# TM4C129ENCPDT register map
File version: 1.0
CPU: CORTEX_M4 1.0, other endian, MPU, FPU, 3 interrupt priority bits
Registers are 32-bit, read-write, reset 0x0 unless marked. A register's access mark holds for its fields unless they carry their own. Offsets are from the block's base; [hi:lo] are bit positions.

## I2C0 — I2C register offsets
Base 0x40020000
Same registers: I2C1 0x40021000, I2C2 0x40022000, I2C3 0x40023000, I2C8 0x400B8000, I2C9 0x400B9000, I2C4 0x400C0000, I2C5 0x400C1000, I2C6 0x400C2000, I2C7 0x400C3000
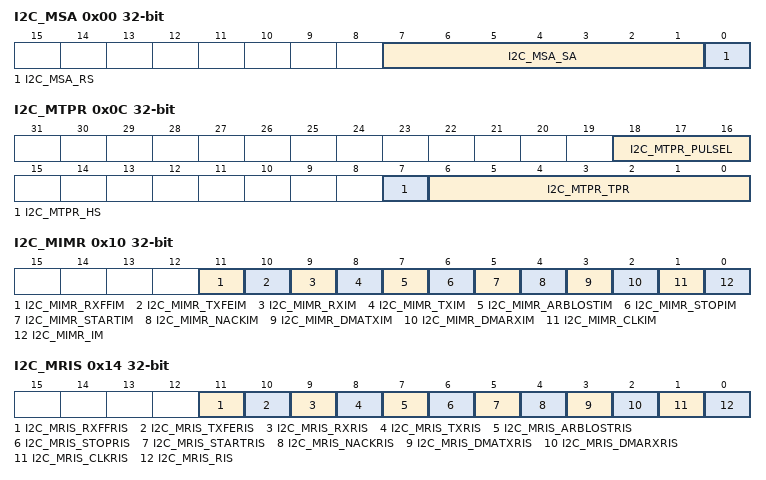
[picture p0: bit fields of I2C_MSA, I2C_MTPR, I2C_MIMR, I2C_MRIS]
0x00 I2C_MSA — I2C Master Slave Address
  [7:1] I2C_MSA_SA — [7:1] I2C Slave Address
  [0] I2C_MSA_RS — [0:0] Receive not send
0x04 I2C_MCS — I2C Master Control/Status
  [31] I2C_MCS_ACTDMARX — [31:31] DMA RX Active Status
  [30] I2C_MCS_ACTDMATX — [30:30] DMA TX Active Status
  [7] I2C_MCS_CLKTO — [7:7] Clock Timeout Error
  [6] I2C_MCS_BURST — [6:6] Burst Enable
  [6] I2C_MCS_BUSBSY — [6:6] Bus Busy
  [5] I2C_MCS_IDLE — [5:5] I2C Idle
  [5] I2C_MCS_QCMD — [5:5] Quick Command
  [4] I2C_MCS_ARBLST — [4:4] Arbitration Lost
  [4] I2C_MCS_HS — [4:4] High-Speed Enable
  [3] I2C_MCS_ACK — [3:3] Data Acknowledge Enable
  [3] I2C_MCS_DATACK — [3:3] Acknowledge Data
  [2] I2C_MCS_ADRACK — [2:2] Acknowledge Address
  [2] I2C_MCS_STOP — [2:2] Generate STOP
  [1] I2C_MCS_ERROR — [1:1] Error
  [1] I2C_MCS_START — [1:1] Generate START
  [0] I2C_MCS_RUN — [0:0] I2C Master Enable
  [0] I2C_MCS_BUSY — [0:0] I2C Busy
0x08 I2C_MDR — I2C Master Data
  [7:0] I2C_MDR_DATA — [7:0] This byte contains the data transferred during a transaction
0x0C I2C_MTPR — I2C Master Timer Period
  [18:16] I2C_MTPR_PULSEL — [18:16] Glitch Suppression Pulse Width
    0=I2C_MTPR_PULSEL_BYPASS (Bypass); 0x10000=1 clock; 0x20000=2 clocks; 0x30000=3 clocks; 0x40000=4 clocks; 0x50000=8 clocks; 0x60000=16 clocks; 0x70000=31 clocks
  [7] I2C_MTPR_HS — [7:7] High-Speed Enable
  [6:0] I2C_MTPR_TPR — [6:0] Timer Period
0x10 I2C_MIMR — I2C Master Interrupt Mask
  [11] I2C_MIMR_RXFFIM — [11:11] Receive FIFO Full Interrupt Mask
  [10] I2C_MIMR_TXFEIM — [10:10] Transmit FIFO Empty Interrupt Mask
  [9] I2C_MIMR_RXIM — [9:9] Receive FIFO Request Interrupt Mask
  [8] I2C_MIMR_TXIM — [8:8] Transmit FIFO Request Interrupt Mask
  [7] I2C_MIMR_ARBLOSTIM — [7:7] Arbitration Lost Interrupt Mask
  [6] I2C_MIMR_STOPIM — [6:6] STOP Detection Interrupt Mask
  [5] I2C_MIMR_STARTIM — [5:5] START Detection Interrupt Mask
  [4] I2C_MIMR_NACKIM — [4:4] Address/Data NACK Interrupt Mask
  [3] I2C_MIMR_DMATXIM — [3:3] Transmit DMA Interrupt Mask
  [2] I2C_MIMR_DMARXIM — [2:2] Receive DMA Interrupt Mask
  [1] I2C_MIMR_CLKIM — [1:1] Clock Timeout Interrupt Mask
  [0] I2C_MIMR_IM — [0:0] Master Interrupt Mask
0x14 I2C_MRIS — I2C Master Raw Interrupt Status
  [11] I2C_MRIS_RXFFRIS — [11:11] Receive FIFO Full Raw Interrupt Status
  [10] I2C_MRIS_TXFERIS — [10:10] Transmit FIFO Empty Raw Interrupt Status
  [9] I2C_MRIS_RXRIS — [9:9] Receive FIFO Request Raw Interrupt Status
  [8] I2C_MRIS_TXRIS — [8:8] Transmit Request Raw Interrupt Status
  [7] I2C_MRIS_ARBLOSTRIS — [7:7] Arbitration Lost Raw Interrupt Status
  [6] I2C_MRIS_STOPRIS — [6:6] STOP Detection Raw Interrupt Status
  [5] I2C_MRIS_STARTRIS — [5:5] START Detection Raw Interrupt Status
  [4] I2C_MRIS_NACKRIS — [4:4] Address/Data NACK Raw Interrupt Status
  [3] I2C_MRIS_DMATXRIS — [3:3] Transmit DMA Raw Interrupt Status
  [2] I2C_MRIS_DMARXRIS — [2:2] Receive DMA Raw Interrupt Status
  [1] I2C_MRIS_CLKRIS — [1:1] Clock Timeout Raw Interrupt Status
  [0] I2C_MRIS_RIS — [0:0] Master Raw Interrupt Status
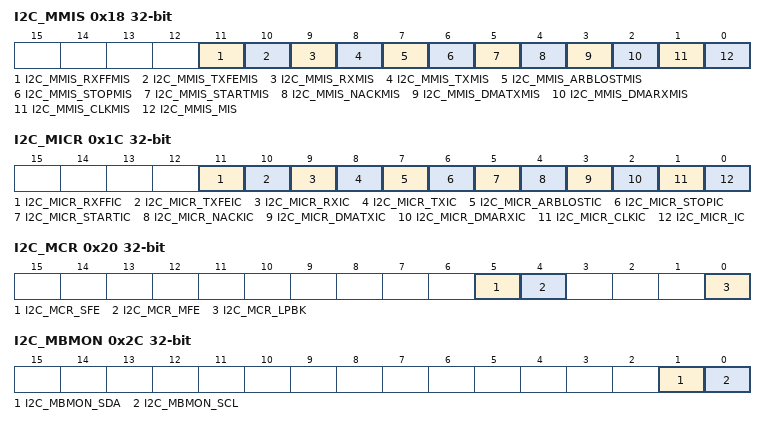
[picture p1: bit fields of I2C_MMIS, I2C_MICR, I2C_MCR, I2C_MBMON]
0x18 I2C_MMIS — I2C Master Masked Interrupt Status
  [11] I2C_MMIS_RXFFMIS — [11:11] Receive FIFO Full Interrupt Mask
  [10] I2C_MMIS_TXFEMIS — [10:10] Transmit FIFO Empty Interrupt Mask
  [9] I2C_MMIS_RXMIS — [9:9] Receive FIFO Request Interrupt Mask
  [8] I2C_MMIS_TXMIS — [8:8] Transmit Request Interrupt Mask
  [7] I2C_MMIS_ARBLOSTMIS — [7:7] Arbitration Lost Interrupt Mask
  [6] I2C_MMIS_STOPMIS — [6:6] STOP Detection Interrupt Mask
  [5] I2C_MMIS_STARTMIS — [5:5] START Detection Interrupt Mask
  [4] I2C_MMIS_NACKMIS — [4:4] Address/Data NACK Interrupt Mask
  [3] I2C_MMIS_DMATXMIS — [3:3] Transmit DMA Interrupt Status
  [2] I2C_MMIS_DMARXMIS — [2:2] Receive DMA Interrupt Status
  [1] I2C_MMIS_CLKMIS — [1:1] Clock Timeout Masked Interrupt Status
  [0] I2C_MMIS_MIS — [0:0] Masked Interrupt Status
0x1C I2C_MICR — I2C Master Interrupt Clear
  [11] I2C_MICR_RXFFIC — [11:11] Receive FIFO Full Interrupt Clear
  [10] I2C_MICR_TXFEIC — [10:10] Transmit FIFO Empty Interrupt Clear
  [9] I2C_MICR_RXIC — [9:9] Receive FIFO Request Interrupt Clear
  [8] I2C_MICR_TXIC — [8:8] Transmit FIFO Request Interrupt Clear
  [7] I2C_MICR_ARBLOSTIC — [7:7] Arbitration Lost Interrupt Clear
  [6] I2C_MICR_STOPIC — [6:6] STOP Detection Interrupt Clear
  [5] I2C_MICR_STARTIC — [5:5] START Detection Interrupt Clear
  [4] I2C_MICR_NACKIC — [4:4] Address/Data NACK Interrupt Clear
  [3] I2C_MICR_DMATXIC — [3:3] Transmit DMA Interrupt Clear
  [2] I2C_MICR_DMARXIC — [2:2] Receive DMA Interrupt Clear
  [1] I2C_MICR_CLKIC — [1:1] Clock Timeout Interrupt Clear
  [0] I2C_MICR_IC — [0:0] Master Interrupt Clear
0x20 I2C_MCR — I2C Master Configuration
  [5] I2C_MCR_SFE — [5:5] I2C Slave Function Enable
  [4] I2C_MCR_MFE — [4:4] I2C Master Function Enable
  [0] I2C_MCR_LPBK — [0:0] I2C Loopback
0x24 I2C_MCLKOCNT — I2C Master Clock Low Timeout Count
  [7:0] I2C_MCLKOCNT_CNTL — [7:0] I2C Master Count
0x2C I2C_MBMON — I2C Master Bus Monitor
  [1] I2C_MBMON_SDA — [1:1] I2C SDA Status
  [0] I2C_MBMON_SCL — [0:0] I2C SCL Status
0x30 I2C_MBLEN — I2C Master Burst Length
  [7:0] I2C_MBLEN_CNTL — [7:0] I2C Burst Length
0x34 I2C_MBCNT — I2C Master Burst Count
  [7:0] I2C_MBCNT_CNTL — [7:0] I2C Master Burst Count
0x800 I2C_SOAR — I2C Slave Own Address
  [6:0] I2C_SOAR_OAR — [6:0] I2C Slave Own Address
0x804 I2C_SCSR — I2C Slave Control/Status
  [31] I2C_SCSR_ACTDMARX — [31:31] DMA RX Active Status
  [30] I2C_SCSR_ACTDMATX — [30:30] DMA TX Active Status
  [5] I2C_SCSR_QCMDRW — [5:5] Quick Command Read / Write
  [4] I2C_SCSR_QCMDST — [4:4] Quick Command Status
  [3] I2C_SCSR_OAR2SEL — [3:3] OAR2 Address Matched
  [2] I2C_SCSR_FBR — [2:2] First Byte Received
  [2] I2C_SCSR_RXFIFO — [2:2] RX FIFO Enable
  [1] I2C_SCSR_TXFIFO — [1:1] TX FIFO Enable
  [1] I2C_SCSR_TREQ — [1:1] Transmit Request
  [0] I2C_SCSR_DA — [0:0] Device Active
  [0] I2C_SCSR_RREQ — [0:0] Receive Request
0x808 I2C_SDR — I2C Slave Data
  [7:0] I2C_SDR_DATA — [7:0] Data for Transfer
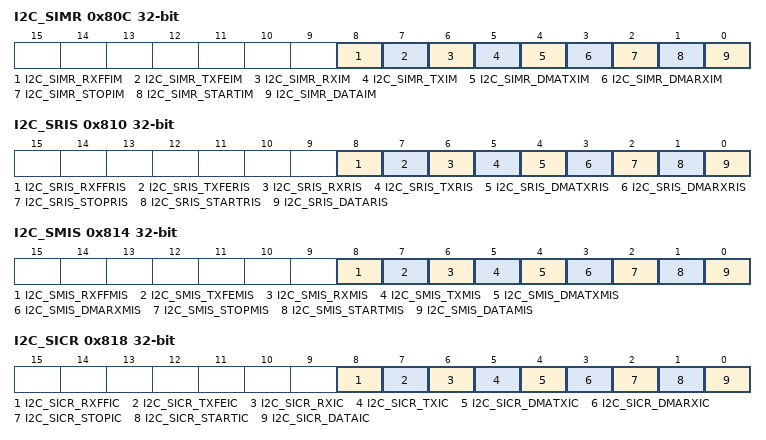
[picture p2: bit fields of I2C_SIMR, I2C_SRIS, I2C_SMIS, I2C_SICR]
0x80C I2C_SIMR — I2C Slave Interrupt Mask
  [8] I2C_SIMR_RXFFIM — [8:8] Receive FIFO Full Interrupt Mask
  [7] I2C_SIMR_TXFEIM — [7:7] Transmit FIFO Empty Interrupt Mask
  [6] I2C_SIMR_RXIM — [6:6] Receive FIFO Request Interrupt Mask
  [5] I2C_SIMR_TXIM — [5:5] Transmit FIFO Request Interrupt Mask
  [4] I2C_SIMR_DMATXIM — [4:4] Transmit DMA Interrupt Mask
  [3] I2C_SIMR_DMARXIM — [3:3] Receive DMA Interrupt Mask
  [2] I2C_SIMR_STOPIM — [2:2] Stop Condition Interrupt Mask
  [1] I2C_SIMR_STARTIM — [1:1] Start Condition Interrupt Mask
  [0] I2C_SIMR_DATAIM — [0:0] Data Interrupt Mask
0x810 I2C_SRIS — I2C Slave Raw Interrupt Status
  [8] I2C_SRIS_RXFFRIS — [8:8] Receive FIFO Full Raw Interrupt Status
  [7] I2C_SRIS_TXFERIS — [7:7] Transmit FIFO Empty Raw Interrupt Status
  [6] I2C_SRIS_RXRIS — [6:6] Receive FIFO Request Raw Interrupt Status
  [5] I2C_SRIS_TXRIS — [5:5] Transmit Request Raw Interrupt Status
  [4] I2C_SRIS_DMATXRIS — [4:4] Transmit DMA Raw Interrupt Status
  [3] I2C_SRIS_DMARXRIS — [3:3] Receive DMA Raw Interrupt Status
  [2] I2C_SRIS_STOPRIS — [2:2] Stop Condition Raw Interrupt Status
  [1] I2C_SRIS_STARTRIS — [1:1] Start Condition Raw Interrupt Status
  [0] I2C_SRIS_DATARIS — [0:0] Data Raw Interrupt Status
0x814 I2C_SMIS — I2C Slave Masked Interrupt Status
  [8] I2C_SMIS_RXFFMIS — [8:8] Receive FIFO Full Interrupt Mask
  [7] I2C_SMIS_TXFEMIS — [7:7] Transmit FIFO Empty Interrupt Mask
  [6] I2C_SMIS_RXMIS — [6:6] Receive FIFO Request Interrupt Mask
  [5] I2C_SMIS_TXMIS — [5:5] Transmit FIFO Request Interrupt Mask
  [4] I2C_SMIS_DMATXMIS — [4:4] Transmit DMA Masked Interrupt Status
  [3] I2C_SMIS_DMARXMIS — [3:3] Receive DMA Masked Interrupt Status
  [2] I2C_SMIS_STOPMIS — [2:2] Stop Condition Masked Interrupt Status
  [1] I2C_SMIS_STARTMIS — [1:1] Start Condition Masked Interrupt Status
  [0] I2C_SMIS_DATAMIS — [0:0] Data Masked Interrupt Status
0x818 I2C_SICR — I2C Slave Interrupt Clear
  [8] I2C_SICR_RXFFIC — [8:8] Receive FIFO Full Interrupt Mask
  [7] I2C_SICR_TXFEIC — [7:7] Transmit FIFO Empty Interrupt Mask
  [6] I2C_SICR_RXIC — [6:6] Receive Request Interrupt Mask
  [5] I2C_SICR_TXIC — [5:5] Transmit Request Interrupt Mask
  [4] I2C_SICR_DMATXIC — [4:4] Transmit DMA Interrupt Clear
  [3] I2C_SICR_DMARXIC — [3:3] Receive DMA Interrupt Clear
  [2] I2C_SICR_STOPIC — [2:2] Stop Condition Interrupt Clear
  [1] I2C_SICR_STARTIC — [1:1] Start Condition Interrupt Clear
  [0] I2C_SICR_DATAIC — [0:0] Data Interrupt Clear
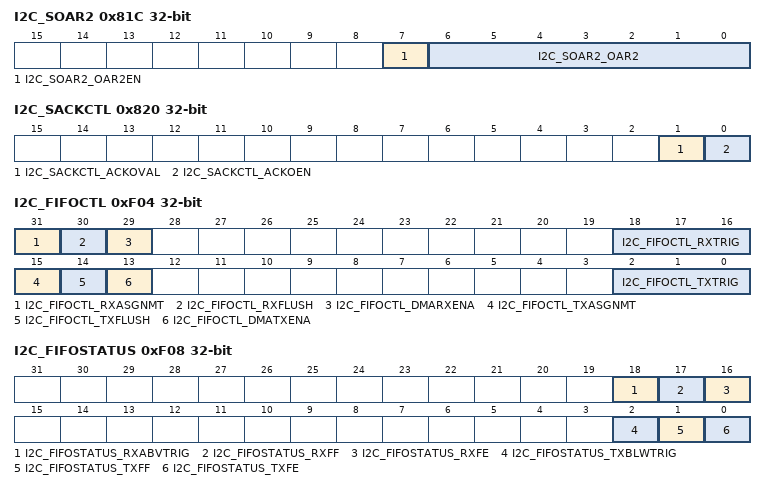
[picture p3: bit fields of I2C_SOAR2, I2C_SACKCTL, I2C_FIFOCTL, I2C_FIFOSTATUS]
0x81C I2C_SOAR2 — I2C Slave Own Address 2
  [7] I2C_SOAR2_OAR2EN — [7:7] I2C Slave Own Address 2 Enable
  [6:0] I2C_SOAR2_OAR2 — [6:0] I2C Slave Own Address 2
0x820 I2C_SACKCTL — I2C Slave ACK Control
  [1] I2C_SACKCTL_ACKOVAL — [1:1] I2C Slave ACK Override Value
  [0] I2C_SACKCTL_ACKOEN — [0:0] I2C Slave ACK Override Enable
0xF00 I2C_FIFODATA
  [7:0] I2C_FIFODATA_DATA — [7:0] I2C TX FIFO Write Data Byte
0xF04 I2C_FIFOCTL — I2C FIFO Control
  [31] I2C_FIFOCTL_RXASGNMT — [31:31] RX Control Assignment
  [30] I2C_FIFOCTL_RXFLUSH — [30:30] RX FIFO Flush
  [29] I2C_FIFOCTL_DMARXENA — [29:29] DMA RX Channel Enable
  [18:16] I2C_FIFOCTL_RXTRIG — [18:16] RX FIFO Trigger
  [15] I2C_FIFOCTL_TXASGNMT — [15:15] TX Control Assignment
  [14] I2C_FIFOCTL_TXFLUSH — [14:14] TX FIFO Flush
  [13] I2C_FIFOCTL_DMATXENA — [13:13] DMA TX Channel Enable
  [2:0] I2C_FIFOCTL_TXTRIG — [2:0] TX FIFO Trigger
0xF08 I2C_FIFOSTATUS
  [18] I2C_FIFOSTATUS_RXABVTRIG — [18:18] RX FIFO Above Trigger Level
  [17] I2C_FIFOSTATUS_RXFF — [17:17] RX FIFO Full
  [16] I2C_FIFOSTATUS_RXFE — [16:16] RX FIFO Empty
  [2] I2C_FIFOSTATUS_TXBLWTRIG — [2:2] TX FIFO Below Trigger Level
  [1] I2C_FIFOSTATUS_TXFF — [1:1] TX FIFO Full
  [0] I2C_FIFOSTATUS_TXFE — [0:0] TX FIFO Empty
0xFC0 I2C_PP — I2C Peripheral Properties
  [0] I2C_PP_HS — [0:0] High-Speed Capable
0xFC4 I2C_PC — I2C Peripheral Configuration
  [0] I2C_PC_HS — [0:0] High-Speed Capable
